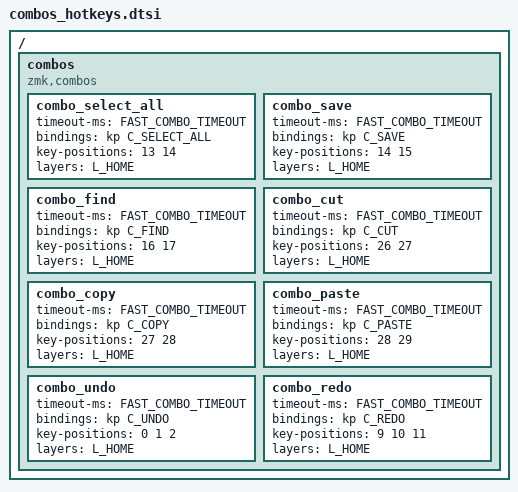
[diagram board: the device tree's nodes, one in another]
/ {
    combos {
        compatible = "zmk,combos";
        combo_select_all { timeout-ms = <FAST_COMBO_TIMEOUT>; bindings = <&kp C_SELECT_ALL>; key-positions = <13 14>; layers = <L_HOME>; };
        combo_save { timeout-ms = <FAST_COMBO_TIMEOUT>; bindings = <&kp C_SAVE>; key-positions = <14 15>; layers = <L_HOME>; };
        combo_find { timeout-ms = <FAST_COMBO_TIMEOUT>; bindings = <&kp C_FIND>; key-positions = <16 17>; layers = <L_HOME>; };
        combo_cut { timeout-ms = <FAST_COMBO_TIMEOUT>; bindings = <&kp C_CUT>; key-positions = <26 27>; layers = <L_HOME>; };
        combo_copy { timeout-ms = <FAST_COMBO_TIMEOUT>; bindings = <&kp C_COPY>; key-positions = <27 28>; layers = <L_HOME>; };
        combo_paste { timeout-ms = <FAST_COMBO_TIMEOUT>; bindings = <&kp C_PASTE>; key-positions = <28 29>; layers = <L_HOME>; };
        combo_undo { timeout-ms = <FAST_COMBO_TIMEOUT>; bindings = <&kp C_UNDO>; key-positions = <0 1 2>; layers = <L_HOME>; };
        combo_redo { timeout-ms = <FAST_COMBO_TIMEOUT>; bindings = <&kp C_REDO>; key-positions = <9 10 11>; layers = <L_HOME>; };
    };
};
